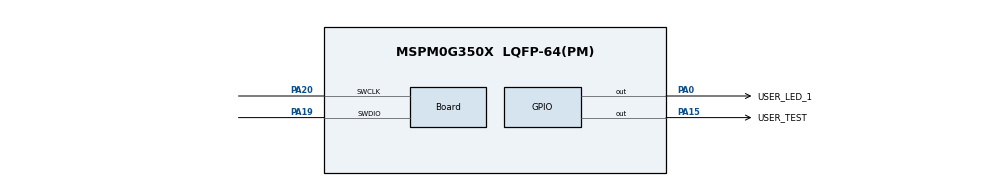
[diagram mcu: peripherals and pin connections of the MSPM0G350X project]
/**
 * @cliArgs --device "MSPM0G350X" --part "Default" --package "LQFP-64(PM)" --product "mspm0_sdk@2.01.00.03"
 * @versions {"tool":"1.22.0+3893"}
 */

/**
 * Import the modules used in this configuration.
 */
const Board         = scripting.addModule("/ti/driverlib/Board");
const GPIO          = scripting.addModule("/ti/driverlib/GPIO", {}, false);
const GPIO1         = GPIO.addInstance();
const MATHACL       = scripting.addModule("/ti/driverlib/MATHACL");
const SYSCTL        = scripting.addModule("/ti/driverlib/SYSCTL");
const ProjectConfig = scripting.addModule("/ti/project_config/ProjectConfig");

/**
 * Write custom configuration values to the imported modules.
 */
Board.peripheral.$assign          = "DEBUGSS";
Board.peripheral.swclkPin.$assign = "PA20";
Board.peripheral.swdioPin.$assign = "PA19";

GPIO1.port                           = "PORTA";
GPIO1.$name                          = "GPIO_LEDS";
GPIO1.associatedPins.create(2);
GPIO1.associatedPins[0].assignedPin  = "0";
GPIO1.associatedPins[0].$name        = "USER_LED_1";
GPIO1.associatedPins[0].initialValue = "SET";
GPIO1.associatedPins[0].pin.$assign  = "PA0";
GPIO1.associatedPins[1].$name        = "USER_TEST";
GPIO1.associatedPins[1].assignedPin  = "15";
GPIO1.associatedPins[1].initialValue = "SET";
GPIO1.associatedPins[1].pin.$assign  = "PA15";

SYSCTL.clockTreeEn           = true;
SYSCTL.forceDefaultClkConfig = true;

ProjectConfig.deviceSpin = "MSPM0G3507";
